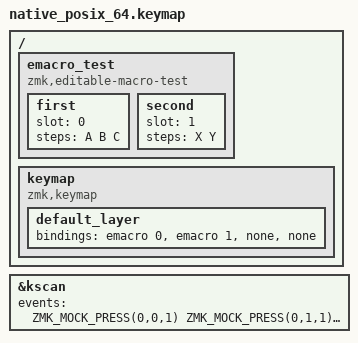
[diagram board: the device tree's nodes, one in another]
/*
 * Copyright (c) 2026 The zmk-editable-macros contributors
 *
 * SPDX-License-Identifier: MIT
 */

/* A second macro triggered while one is playing waits its turn; nothing interleaves. */

#include "../common.dtsi"

/ {
    emacro_test {
        compatible = "zmk,editable-macro-test";

        first {
            slot = <0>;
            steps = <A B C>;
        };

        second {
            slot = <1>;
            steps = <X Y>;
        };
    };

    keymap {
        compatible = "zmk,keymap";

        default_layer {
            bindings = <&emacro 0 &emacro 1 &none &none>;
        };
    };
};

&kscan {
    events = <
        ZMK_MOCK_PRESS(0,0,1) ZMK_MOCK_PRESS(0,1,1)
        ZMK_MOCK_RELEASE(0,0,1) ZMK_MOCK_RELEASE(0,1,100)
    >;
};
